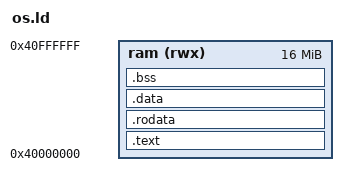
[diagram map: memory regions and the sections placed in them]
OUTPUT_ARCH( "riscv" )
ENTRY( _start )

MEMORY
{
    ram (rwx) : ORIGIN = 0x40000000, LENGTH = 0x1000000
}

SECTIONS
{
    .text : {
        . = ALIGN(4096);
        PROVIDE(_text_start = .);
        *(.text .text.*)
        PROVIDE(_text_end = .);
    } >ram

    .rodata : {
        . = ALIGN(4096);
        PROVIDE(_rodata_start = .);
        *(.rodata .rodata.*)
        PROVIDE(_rodata_end = .);
    } >ram

    .data : {
        . = ALIGN(4096);
        PROVIDE(_data_start = .);
        *(.sdata .sdata.*)
        *(.data .data.*)
        PROVIDE(_data_end = .);
    } >ram

    .bss : {
        . = ALIGN(4096);
        PROVIDE(_bss_start = .);
        *(.sbss .sbss.*)
        *(.bss .bss.*)
        *(COMMON)
        PROVIDE(_bss_end = .);
    } >ram

    PROVIDE(_memory_start = ORIGIN(ram));
    PROVIDE(_memory_end = ORIGIN(ram) + LENGTH(ram));
    
    PROVIDE(_heap_start = _bss_end);
    PROVIDE(_heap_size = _memory_end - _heap_start);
}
